# ESP32S31_PLATFORM register map
Vendor: Espressif; Series: ESP32-S31; File version: 1
ESP32-S31 platform registers the host reads through the chip's JTAG, never firmware: no PAC is generated from this model. ESP-HAL owns these blocks at runtime.
Registers are 32-bit, read-only, reset 0x0 unless marked. A register's access mark holds for its fields unless they carry their own. Offsets are from the block's base; lines under a group give offsets from that group; [hi:lo] are bit positions; {n}, {i} and the like mark numbered series; 'fields as' and 'values as' point back to an identical list; <NAME> marks a mode.

## Memory map
0x20701000 LP_AON_CLKRST — Low-power always-on clock/reset registers: the reset cause of HP core 0, which the stand reads after a power cycle.

## LP_AON_CLKRST — Low-power always-on clock/reset registers: the reset cause of HP core 0, which the stand reads after a power cycle.
Base 0x20701000
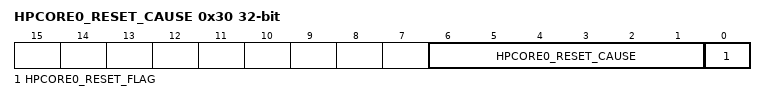
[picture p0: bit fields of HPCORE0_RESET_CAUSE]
0x30 HPCORE0_RESET_CAUSE — Why HP core 0 last left reset. It holds until the next reset, so a host reads it through JTAG after the core returned.
  [6:1] HPCORE0_RESET_CAUSE — The reset cause code: one is a power-on reset; others are system, watchdog, brown-out, USB Serial/JTAG and JTAG resets.
  [0] HPCORE0_RESET_FLAG — Set when HP core 0 left reset.

## Licence text in the file
MIT OR Apache-2.0
